# STM32U083 register map
File version: 0.2
CPU: CM0+ r0p1, little endian, MPU, no FPU, 4 interrupt priority bits
Registers are 32-bit, read-write, reset 0x0 unless marked. A register's access mark holds for its fields unless they carry their own. Offsets are from the block's base; [hi:lo] are bit positions.

## TIM6 — TIM6 address block description
Base 0x40001000
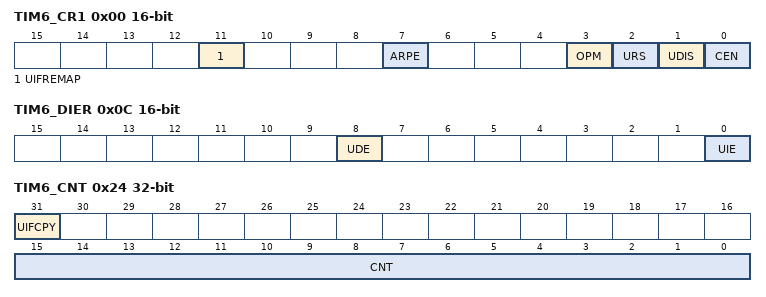
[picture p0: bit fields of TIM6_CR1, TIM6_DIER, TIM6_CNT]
0x00 TIM6_CR1 16-bit — TIM6 control register 1
  [11] UIFREMAP — UIF status bit remapping
    0=No remapping. UIF status bit is not copied to TIMx_CNT register bit 31.; 1=Remapping enabled. UIF status bit is copied to TIMx_CNT register bit 31.
  [7] ARPE — Auto-reload preload enable
    0=TIMx_ARR register is not buffered; 1=TIMx_ARR register is buffered
  [3] OPM — One-pulse mode
    0=Counter is not stopped at update event; 1=Counter stops counting at the next update event (clearing the CEN bit)
  [2] URS — Update request source This bit is set and cleared by software to select the UEV event sources. Counter overflow/underflow Setting the UG bit Update generation through the slave mode controller
    0=Any of the following events generates an update interrupt or DMA request if enabled. These events can be:; 1=Only counter overflow/underflow generates an update interrupt or DMA request if enabled
  [1] UDIS — Update disable This bit is set and cleared by software to enable/disable UEV event generation. Counter overflow/underflow Setting the UG bit Update generation through the slave mode controller Buffered registers are then loaded with their preload values.
    0=UEV enabled. The Update (UEV) event is generated by one of the following events:; 1=UEV disabled. The Update event is not generated, shadow registers keep their value (ARR, PSC). However the counter and the prescaler are reinitialized if the UG bit is set or if a hardware reset is received from the slave mode controller.
  [0] CEN — Counter enable Note: Gated mode can work only if the CEN bit has been previously set by software. However trigger mode can set the CEN bit automatically by hardware. CEN is cleared automatically in one-pulse mode, when an update event occurs.
    0=Counter disabled; 1=Counter enabled
0x04 TIM6_CR2 16-bit — TIM6 control register 2
  [6:4] MMS — Master mode selection These bits are used to select the information to be sent in master mode to slave timers for synchronization (TRGO). The combination is as follows: When the Counter Enable signal is controlled by the trigger input, there is a delay on TRGO, except if the master/slave mode is selected (see the MSM bit description in the TIMx_SMCR register). Note: The clock of the slave timer or ADC must be enabled prior to receive events from the master timer, and must not be changed on-the-fly while triggers are received from the master timer.
    0=Reset - the UG bit from the TIMx_EGR register is used as a trigger output (TRGO). If reset is generated by the trigger input (slave mode controller configured in reset mode) then the signal on TRGO is delayed compared to the actual reset.; 1=Enable - the Counter enable signal, CNT_EN, is used as a trigger output (TRGO). It is useful to start several timers at the same time or to control a window in which a slave timer is enabled. The Counter Enable signal is generated by a logic OR between CEN control bit and the trigger input when configured in gated mode.; 2=Update - The update event is selected as a trigger output (TRGO). For instance a master timer can then be used as a prescaler for a slave timer.
0x0C TIM6_DIER 16-bit — TIM6 DMA/Interrupt enable register
  [8] UDE — Update DMA request enable
    0=Update DMA request disabled; 1=Update DMA request enabled
  [0] UIE — Update interrupt enable
    0=Update interrupt disabled; 1=Update interrupt enabled
0x10 TIM6_SR 16-bit — TIM6 status register
  [0] UIF — Update interrupt flag This bit is set by hardware on an update event. It is cleared by software. At overflow or underflow regarding the repetition counter value and if UDIS = 0 in the TIMx_CR1 register. When CNT is reinitialized by software using the UG bit in the TIMx_EGR register, if URS1=10 and UDIS1=10 in the TIMx_CR1 register.
    0=No update occurred; 1=Update interrupt pending. This bit is set by hardware when the registers are updated:
0x14 TIM6_EGR 16-bit wo — TIM6 event generation register
  [0] UG — Update generation This bit can be set by software, it is automatically cleared by hardware.
    0=No action; 1=Re-initializes the timer counter and generates an update of the registers. Note that the prescaler counter is cleared too (but the prescaler ratio is not affected).
0x24 TIM6_CNT access per field — TIM6 counter
  [31] UIFCPY ro — UIF Copy This bit is a read-only copy of the UIF bit of the TIMx_ISR register. If the UIFREMAP bit in TIMx_CR1 is reset, bit 31 is reserved and read as 0.
  [15:0] CNT rw — Counter value
0x28 TIM6_PSC 16-bit — TIM6 prescaler
  [15:0] PSC — Prescaler value The counter clock frequency CK_CNT is equal to f<sub>CK_PSC</sub> / (PSC[15:0] + 1). PSC contains the value to be loaded into the active prescaler register at each update event. (including when the counter is cleared through UG bit of TIMx_EGR register or through trigger controller when configured in reset mode).
0x2C TIM6_ARR 16-bit reset 0xFFFF — TIM6 auto-reload register
  [15:0] ARR — Prescaler value ARR is the value to be loaded into the actual auto-reload register. Refer to Section123.3.1: Time-base unit on page1596 for more details about ARR update and behavior. The counter is blocked while the auto-reload value is null.

## TIM7 — TIM7 address block description
Base 0x40001400
Registers as TIM6 (with TIM6 read as TIM7).
